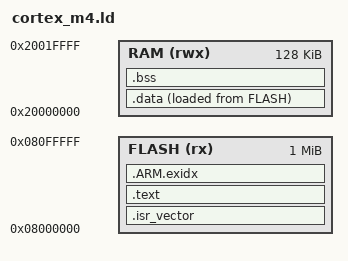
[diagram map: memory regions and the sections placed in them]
/* Generic STM32F4-class memory map: 1 MiB flash, 128 KiB SRAM. */
ENTRY(Reset_Handler)

MEMORY
{
  FLASH (rx)  : ORIGIN = 0x08000000, LENGTH = 1024K
  RAM   (rwx) : ORIGIN = 0x20000000, LENGTH = 128K
}

_estack = ORIGIN(RAM) + LENGTH(RAM);

SECTIONS
{
  .isr_vector : { KEEP(*(.isr_vector)) } > FLASH

  .text :
  {
    *(.text*)
    *(.rodata*)
    KEEP(*(.init))
    KEEP(*(.fini))
    . = ALIGN(4);
  } > FLASH

  .ARM.exidx : { *(.ARM.exidx* .gnu.linkonce.armexidx.*) } > FLASH

  _sidata = LOADADDR(.data);
  .data :
  {
    . = ALIGN(4);
    _sdata = .;
    *(.data*)
    . = ALIGN(4);
    _edata = .;
  } > RAM AT > FLASH

  .bss (NOLOAD) :
  {
    . = ALIGN(4);
    _sbss = .;
    *(.bss*)
    *(COMMON)
    . = ALIGN(4);
    _ebss = .;
  } > RAM

  end = .;
  _end = .;
}
